# RZT2H register map
Vendor: Renesas Electronics Corporation; Series: RZT; File version: 1.00.00
CPU: other r0p0, little endian, MPU, no FPU, VTOR, 4 interrupt priority bits, 624 interrupts
Registers are 32-bit, read-write, reset 0x0 unless marked. A register's access mark holds for its fields unless they carry their own. Offsets are from the block's base; [hi:lo] are bit positions; {n}, {i} and the like mark numbered series; 'fields as' and 'values as' point back to an identical list.

## PCIE0 (part 1 of 2) — PCI Express 3.0 Interface 0
Base 0x92100000
Same registers: PCIE1 0x92110000
{0x80+4i} PCI_EP_REQDATA{i} (i=0..2) reset not defined — Request Data Register {i}
{0x80+4i} PCI_RC_REQDATA{i} (i=0..2) reset not defined (alternate view of PCI_EP_REQDATA{i}) — Request Data Register {i}
0x8C PCI_EP_REQRCVDAT ro reset not defined — Request Receive Data Register
0x8C PCI_RC_REQRCVDAT ro reset not defined (alternate view of PCI_EP_REQRCVDAT) — Request Receive Data Register
0x90 PCI_EP_REQADR1 reset not defined — Request Address Register 1
0x90 PCI_RC_REQADR1 reset not defined (alternate view of PCI_EP_REQADR1) — Request Address Register 1
0x94 PCI_EP_REQADR2 reset not defined — Request Address Register 2
0x94 PCI_RC_REQADR2 reset not defined (alternate view of PCI_EP_REQADR2) — Request Address Register 2
0x98 PCI_EP_REQBE reset 0xF — Request Byte Enable Register
  [3:0] RBE — Request Byte Enable
    0=Byte Enable enabled; 1=Byte Enable disabled
0x98 PCI_RC_REQBE reset 0xF (alternate view of PCI_EP_REQBE) — Request Byte Enable Register
  fields as PCI_EP_REQBE
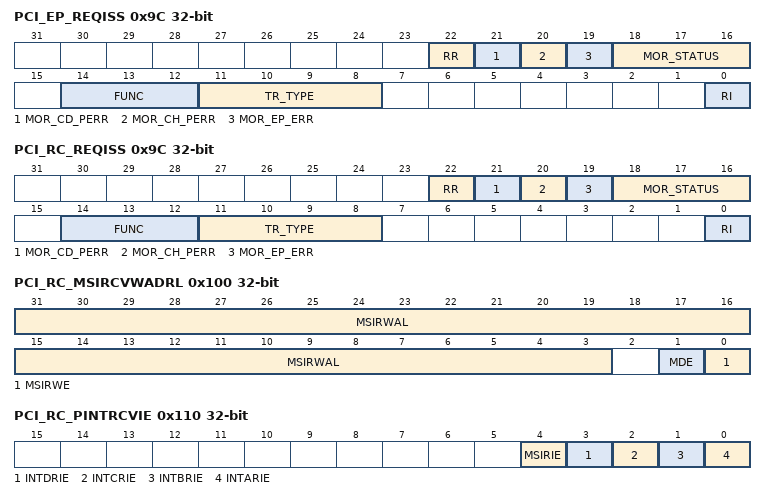
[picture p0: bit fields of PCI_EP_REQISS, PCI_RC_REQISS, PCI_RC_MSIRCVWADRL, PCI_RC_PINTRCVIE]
0x9C PCI_EP_REQISS — Request Issue Register
  [22] RR ro — Request Rejection
    0=Normal state (Request issued); 1=Rejection
  [21] MOR_CD_PERR ro — It is set to 1 when a data error occurs in the Completion TLP for the Non-Posted request issued by this register.
  [20] MOR_CH_PERR ro — It is set to 1 when a header error occurs in the Completion TLP for the Non-Posted request issued by this register.
  [19] MOR_EP_ERR ro — It is set to 1 when a Poisoned Completion TLP for a Non-Posted request issued by this register is received.
  [18:16] MOR_STATUS ro — These bits retain the MOR Status of Completion TLP for Non-Posted requests issued.
    0=Successful Completion (SC); 1=Unsupported Request (UR); 2=Configuration Request Retry Status (CRS) (not supported); 3=Completion Timeout; 4=Completer Abort (CA); 5=Unexpected Completion and mismatched type (Lock Completion responds to non-Lock Request); 7=Overrun Completion length
  [14:12] FUNC — Set the function of Request.
  [11:8] TR_TYPE — Set the type of Request.
  [0] RI — Request Issue
    0=Write: No operation. Read: Request can be accepted. (Indicates that the processing of the issued Request has ended.); 1=Write: Request issuance. Read: Processing Request. (Indicates that the issued Request is being processed.)
0x9C PCI_RC_REQISS (alternate view of PCI_EP_REQISS) — Request Issue Register
  fields as PCI_EP_REQISS
0x100 PCI_RC_MSIRCVWADRL — MSI Receive Window Address (Lower) Register
  [31:3] MSIRWAL — MSI Receive Window Address (Lower)
  [1] MDE — Message Data Enabled
    1=Used (multiple interrupts)
  [0] MSIRWE — MSI Receive Window Enable
    0=Window is disabled; 1=Window is enabled
0x104 PCI_RC_MSIRCVWADRU — MSI Receive Window Address (Upper) Register
  [31:0] MSIRWAU — MSI Receive Window Address (Upper)
0x108 PCI_RC_MSIRCVWMSKL reset 0x3 — MSI Receive Window Mask (Lower) Register
  [31:0] MSIRWML — MSI Receive Window Mask (Lower)
0x10C PCI_RC_MSIRCVWMSKU — MSI Receive Window Mask (Upper) Register
  [30:0] MSIRWMU — MSI Receive Window Mask (Upper)
0x110 PCI_RC_PINTRCVIE — PCI INTx Receive Interrupt Enable Register
  [all] fields
    0=disable; 1=enable
  [4] MSIRIE — MSI Receive Interrupt Enable
  [3] INTDRIE — INTD Receive Interrupt Enable
  [2] INTCRIE — INTC Receive Interrupt Enable
  [1] INTBRIE — INTB Receive Interrupt Enable
  [0] INTARIE — INTA Receive Interrupt Enable
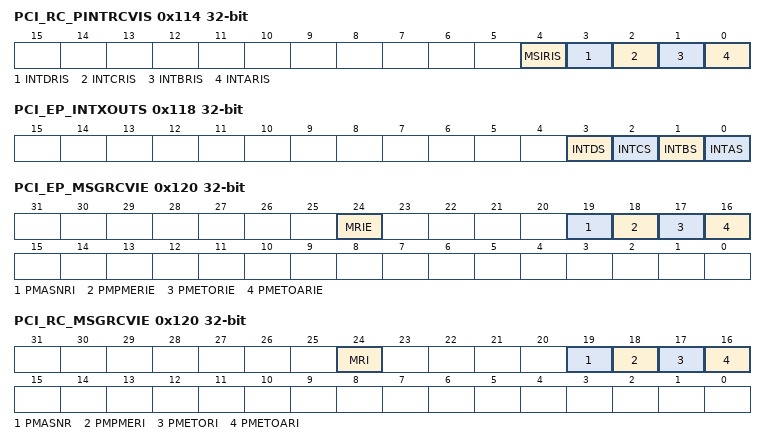
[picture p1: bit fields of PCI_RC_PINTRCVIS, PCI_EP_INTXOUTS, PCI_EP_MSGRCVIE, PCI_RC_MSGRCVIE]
0x114 PCI_RC_PINTRCVIS — PCI INTx Receive Interrupt Status Register
  [4] MSIRIS — MSI Receive Interrupt Status
  [3] INTDRIS — INTD Receive Interrupt Status
  [2] INTCRIS — INTC Receive Interrupt Status
  [1] INTBRIS — INTB Receive Interrupt Status
  [0] INTARIS — INTA Receive Interrupt Status
0x118 PCI_EP_INTXOUTS ro — PCI INTx Out Status Register
  [all] fields
    0=Deassert; 1=Assert
  [3] INTDS — INTD Status
  [2] INTCS — INTC Status
  [1] INTBS — INTB Status
  [0] INTAS — INTA Status
0x120 PCI_EP_MSGRCVIE — Message Receive Interrupt Enable Register
  [24] MRIE — Message Receive Interrupt Enable
    0=enable; 1=disable
  [19] PMASNRI — PM_Active_State_Nak Receive Interrupt
    0=Disable; 1=Enable
  [18] PMPMERIE — PM_PME Receive Interrupt Enable
    0=Disable; 1=Enable
  [17] PMETORIE — PME_Turn_Off Receive Interrupt Enable
    0=Disable; 1=Enable
  [16] PMETOARIE — PME_TO_Ack Receive Interrupt Enable
    0=Disable; 1=Enable
0x120 PCI_RC_MSGRCVIE (alternate view of PCI_EP_MSGRCVIE) — Message Receive Interrupt Enable Register
  [24] MRI — Message Receive Interrupt
    0=enable; 1=disable
  [19] PMASNR — PM_Active_State_Nak Receive
    0=Disable; 1=Enable
  [18] PMPMERI — PM_PME Receive Interrupt
    0=Disable; 1=Enable
  [17] PMETORI — PME_Turn_Off Receive Interrupt
    0=Disable; 1=Enable
  [16] PMETOARI — PME_TO_Ack Receive Interrupt
    0=Disable; 1=Enable
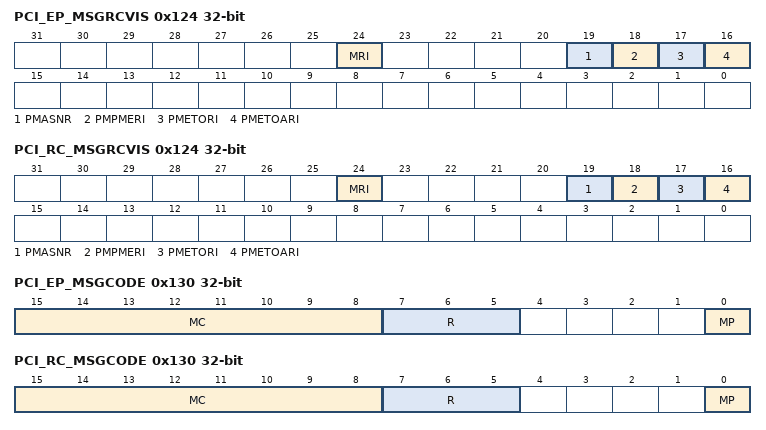
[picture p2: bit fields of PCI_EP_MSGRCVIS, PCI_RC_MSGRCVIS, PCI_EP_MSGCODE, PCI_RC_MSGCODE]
0x124 PCI_EP_MSGRCVIS — Message Receive Interrupt Status Register
  [24] MRI — Message Receive Interrupt
  [19] PMASNR — PM_Active_State_Nak Receive
  [18] PMPMERI — PM_PME Receive Interrupt
  [17] PMETORI — PME_Turn_Off Receive Interrupt
  [16] PMETOARI — PME_TO_Ack Receive Interrupt
0x124 PCI_RC_MSGRCVIS (alternate view of PCI_EP_MSGRCVIS) — Message Receive Interrupt Status Register
  fields as PCI_EP_MSGRCVIS
0x130 PCI_EP_MSGCODE ro — Message Code Register
  [15:8] MC — Message Code
  [7:5] R — Routing
  [0] MP — Message Payload
    0=Msg (Without Payload); 1=MsgD (with Payload)
0x130 PCI_RC_MSGCODE ro (alternate view of PCI_EP_MSGCODE) — Message Code Register
  fields as PCI_EP_MSGCODE
0x134 PCI_EP_MSGDATA ro — Message Data Register
0x134 PCI_RC_MSGDATA ro (alternate view of PCI_EP_MSGDATA) — Message Data Register
0x138 PCI_EP_MSGH3DW ro — Message Header 3rdDW Register
0x138 PCI_RC_MSGH3DW ro (alternate view of PCI_EP_MSGH3DW) — Message Header 3rdDW Register
0x13C PCI_EP_MSGH4DW ro — Message Header 4thDW Register
0x13C PCI_RC_MSGH4DW ro (alternate view of PCI_EP_MSGH4DW) — Message Header 4thDW Register
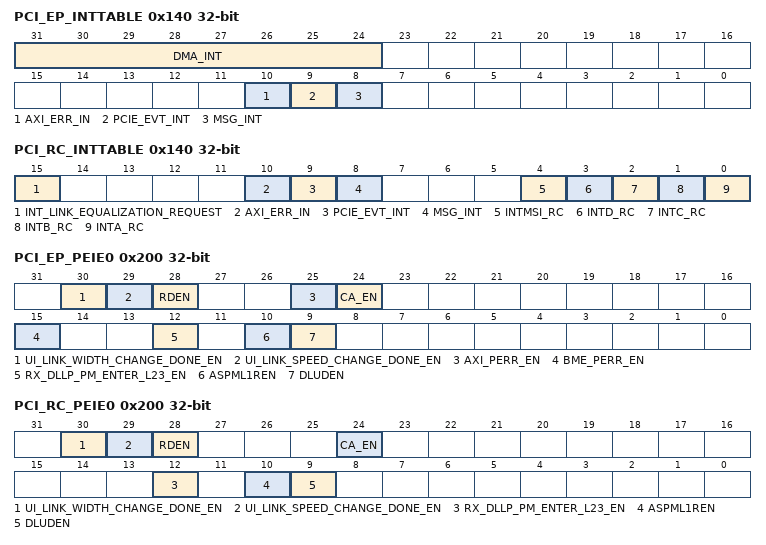
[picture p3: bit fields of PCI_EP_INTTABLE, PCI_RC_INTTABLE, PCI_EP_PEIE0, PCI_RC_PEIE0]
0x140 PCI_EP_INTTABLE ro — Interrupt Table Register
  [31:24] DMA_INT — DMA_INT interrupt signal monitor
  [10] AXI_ERR_IN — Error interrupt signal monitor
  [9] PCIE_EVT_INT — Event interrupt signal monitor
  [8] MSG_INT — Message interrupt signal monitor
0x140 PCI_RC_INTTABLE ro (alternate view of PCI_EP_INTTABLE) — Interrupt Table Register
  [15] INT_LINK_EQUALIZATION_REQUEST — LINK_EQUALIZATION_REQUEST Interrupt signal level monitor
  [10] AXI_ERR_IN — Error interrupt signal monitor
  [9] PCIE_EVT_INT — Event interrupt signal monitor
  [8] MSG_INT — Message interrupt signal monitor
  [4] INTMSI_RC — INT_MSI interrupt signal monitor
  [3] INTD_RC — INTD_RC interrupt signal monitor
  [2] INTC_RC — INTC_RC interrupt signal monitor
  [1] INTB_RC — INTB_RC interrupt signal monitor
  [0] INTA_RC — INTA_RC interrupt signal monitor
0x200 PCI_EP_PEIE0 — PCIe Event Interrupt Enable 0 Register
  [all] fields
    0=Disable; 1=Enable
  [30] UI_LINK_WIDTH_CHANGE_DONE_EN — Up/Down Configure operation complete interrupt enable
  [29] UI_LINK_SPEED_CHANGE_DONE_EN — Speed change operation completion interrupt enable
  [28] RDEN — Request complete interrupt enable
  [25] AXI_PERR_EN — Enable AXIM RAM parity error interrupt
  [24] CA_EN — CA (Completer Abort) interrupt enable
  [15] BME_PERR_EN — Enable BME Parity Error interrupt.
  [12] RX_DLLP_PM_ENTER_L23_EN — RX_DLLP_PM_ENTER_L23 interrupt enable
  [10] ASPML1REN — ASPM L1 Rejected interrupt enable
  [9] DLUDEN — DL_UpDown EN
0x200 PCI_RC_PEIE0 (alternate view of PCI_EP_PEIE0) — PCIe Event Interrupt Enable 0 Register
  [all] fields
    0=Disable; 1=Enable
  [30] UI_LINK_WIDTH_CHANGE_DONE_EN — Up/Down Configure operation complete interrupt enable
  [29] UI_LINK_SPEED_CHANGE_DONE_EN — Speed change operation completion interrupt enable
  [28] RDEN — Request complete interrupt enable
  [24] CA_EN — CA (Completer Abort) interrupt enable
  [12] RX_DLLP_PM_ENTER_L23_EN — RX_DLLP_PM_ENTER_L23 interrupt enable
  [10] ASPML1REN — ASPM L1 Rejected interrupt enable
  [9] DLUDEN — DL_UpDown EN
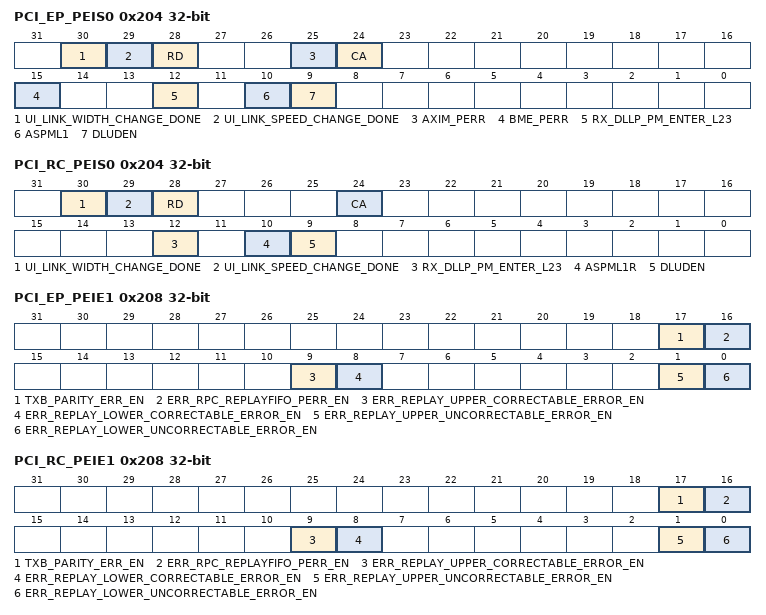
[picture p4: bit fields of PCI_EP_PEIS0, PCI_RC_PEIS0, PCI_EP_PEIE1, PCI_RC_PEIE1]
0x204 PCI_EP_PEIS0 — PCIe Event Interrupt Status 0 Register
  [30] UI_LINK_WIDTH_CHANGE_DONE — Indicates completion of Up/DownConfigure operation.
  [29] UI_LINK_SPEED_CHANGE_DONE — Indicates completion of Speed Change operation.
  [28] RD — Request Done
  [25] AXIM_PERR — Indicates that a parity error has occurred in the AXIM RAM.
  [24] CA — Indicates that the device has responded with CA (Completer Abort).
  [15] BME_PERR — Indicates that a parity error has occurred in the BME RAM.
  [12] RX_DLLP_PM_ENTER_L23 — Indicates transition to L2/L3 State in Power Management control.
  [10] ASPML1
  [9] DLUDEN — DL_UpDown EN
0x204 PCI_RC_PEIS0 (alternate view of PCI_EP_PEIS0) — PCIe Event Interrupt Status 0 Register
  [30] UI_LINK_WIDTH_CHANGE_DONE — Indicates completion of Up/DownConfigure operation.
  [29] UI_LINK_SPEED_CHANGE_DONE — Indicates completion of Speed Change operation.
  [28] RD — Request Done
  [24] CA — Indicates that the device has responded with CA (Completer Abort).
  [12] RX_DLLP_PM_ENTER_L23 — Indicates transition to L2/L3 State in Power Management control.
  [10] ASPML1R — ASPM L1 Rejected
  [9] DLUDEN — DL_UpDown EN
0x208 PCI_EP_PEIE1 — PCIe Event Interrupt Enable 1 Register
  [17] TXB_PARITY_ERR_EN — Enable the TXB_PARITY_ERR interrupt.
    0=Do not allow; 1=Allow
  [16] ERR_RPC_REPLAYFIFO_PERR_EN — Enable ERR_RPC_REPLAYFIFO_PERR interrupts.
    0=Disable; 1=Enable
  [9] ERR_REPLAY_UPPER_CORRECTABLE_ERROR_EN — Enable ERR_REPLAY_UPPER_CORRECTABLE_ERROR interrupts.
    0=Disable; 1=Enable
  [8] ERR_REPLAY_LOWER_CORRECTABLE_ERROR_EN — Enable ERR_REPLAY_LOWER_CORRECTABLE_ERROR interrupts.
    0=Disable; 1=Enable
  [1] ERR_REPLAY_UPPER_UNCORRECTABLE_ERROR_EN — Enable ERR_REPLAY_UPPER_UNCORRECTABLE_ERROR interrupts.
    0=Disable; 1=Enable
  [0] ERR_REPLAY_LOWER_UNCORRECTABLE_ERROR_EN — Enable ERR_REPLAY_LOWER_UNCORRECTABLE_ERROR interrupts.
    0=Disable; 1=Enable
0x208 PCI_RC_PEIE1 (alternate view of PCI_EP_PEIE1) — PCIe Event Interrupt Enable 1 Register
  fields as PCI_EP_PEIE1
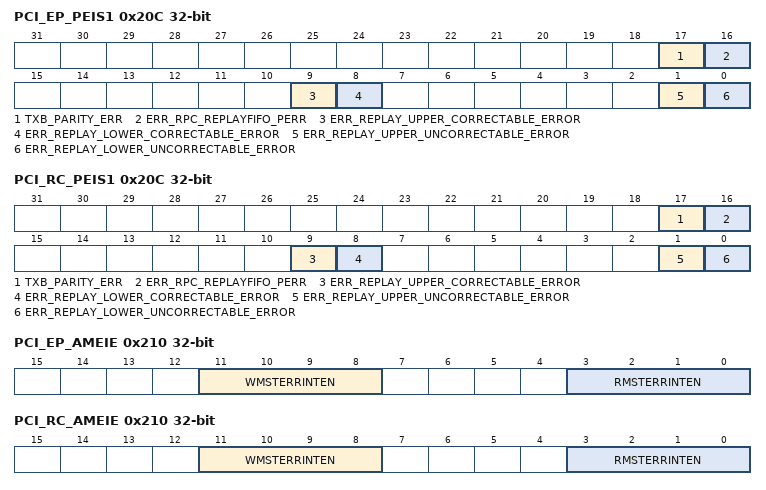
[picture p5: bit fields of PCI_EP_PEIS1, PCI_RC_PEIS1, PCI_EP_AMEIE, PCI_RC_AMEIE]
0x20C PCI_EP_PEIS1 — PCIe Event Interrupt Status 1 Register
  [17] TXB_PARITY_ERR — TXB_PARITY_ERR interrupt
  [16] ERR_RPC_REPLAYFIFO_PERR — ERR_RPC_REPLAYFIFO_PERR interrupt
  [9] ERR_REPLAY_UPPER_CORRECTABLE_ERROR — ERR_REPLAY_UPPER_CORRECTABLE_ERROR interrupt
  [8] ERR_REPLAY_LOWER_CORRECTABLE_ERROR — ERR_REPLAY_LOWER_CORRECTABLE_ERROR interrupt
  [1] ERR_REPLAY_UPPER_UNCORRECTABLE_ERROR — ERR_REPLAY_UPPER_UNCORRECTABLE_ERROR interrupt
  [0] ERR_REPLAY_LOWER_UNCORRECTABLE_ERROR — ERR_REPLAY_LOWER_UNCORRECTABLE_ERROR interrupt
0x20C PCI_RC_PEIS1 (alternate view of PCI_EP_PEIS1) — PCIe Event Interrupt Status 1 Register
  fields as PCI_EP_PEIS1
0x210 PCI_EP_AMEIE — AXI Master Error Interrupt Enable Register
  [11:8] WMSTERRINTEN — Write MSTERR INT Enable
    0=Disable; 1=Enable
  [3:0] RMSTERRINTEN — Read MSTERR INT Enable
    0=Disable; 1=Enable
0x210 PCI_RC_AMEIE (alternate view of PCI_EP_AMEIE) — AXI Master Error Interrupt Enable Register
  fields as PCI_EP_AMEIE
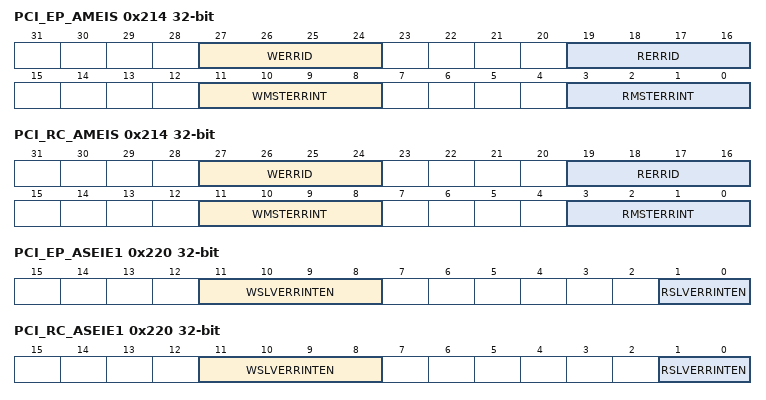
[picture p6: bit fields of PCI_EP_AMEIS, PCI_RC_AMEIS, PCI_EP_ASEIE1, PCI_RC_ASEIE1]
0x214 PCI_EP_AMEIS — AXI Master Error Interrupt Status Register
  [27:24] WERRID ro — Write ERR ID
    0=normal access; other=Others (Error ID)
  [19:16] RERRID ro — Read ERR ID
    0=normal access; other=Others (Error ID)
  [11:8] WMSTERRINT — Write MSTERR INT
  [3:0] RMSTERRINT — Read MSTERR INT
0x214 PCI_RC_AMEIS (alternate view of PCI_EP_AMEIS) — AXI Master Error Interrupt Status Register
  fields as PCI_EP_AMEIS
0x220 PCI_EP_ASEIE1 — AXI Slave Error Interrupt Enable 1 Register
  [11:8] WSLVERRINTEN — Write SLVERR INT EN
    0=Disable; 1=Enable
  [1:0] RSLVERRINTEN — Read SLVERR INT EN
    0=Disable; 1=Enable
0x220 PCI_RC_ASEIE1 (alternate view of PCI_EP_ASEIE1) — AXI Slave Error Interrupt Enable 1 Register
  fields as PCI_EP_ASEIE1
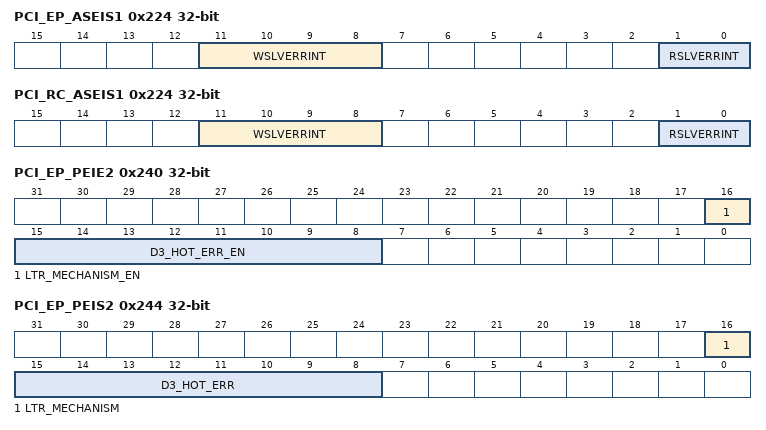
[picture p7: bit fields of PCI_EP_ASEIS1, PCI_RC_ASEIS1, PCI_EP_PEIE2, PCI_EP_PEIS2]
0x224 PCI_EP_ASEIS1 — AXI Slave Error Interrupt Status 1 Register
  [11:8] WSLVERRINT — Write SLVERR INT
  [1:0] RSLVERRINT — Read SLVERR INT
0x224 PCI_RC_ASEIS1 (alternate view of PCI_EP_ASEIS1) — AXI Slave Error Interrupt Status 1 Register
  fields as PCI_EP_ASEIS1
0x230 PCI_EP_ASEIS3 ro — AXI Slave Error Interrupt Status 3 Register
0x230 PCI_RC_ASEIS3 ro (alternate view of PCI_EP_ASEIS3) — AXI Slave Error Interrupt Status 3 Register
0x240 PCI_EP_PEIE2 — PCIe Event Interrupt Enable 2 Register
  [16] LTR_MECHANISM_EN — Interrupt enable for the ability to detect changes in CFG_LTR_MECHANISM
  [15:8] D3_HOT_ERR_EN
0x244 PCI_EP_PEIS2 — PCIe Event Interrupt Status 2 Register
  [16] LTR_MECHANISM — Status to detect and notify changes in CFG_LTR_MECHANISM
  [15:8] D3_HOT_ERR
0x300 PCI_EP_PERM — Permission Register
  [1] PHY_REG_CLK_EN — Write enable for Physical Layer Control/Status Registers.
    0=Disable; 1=Enable
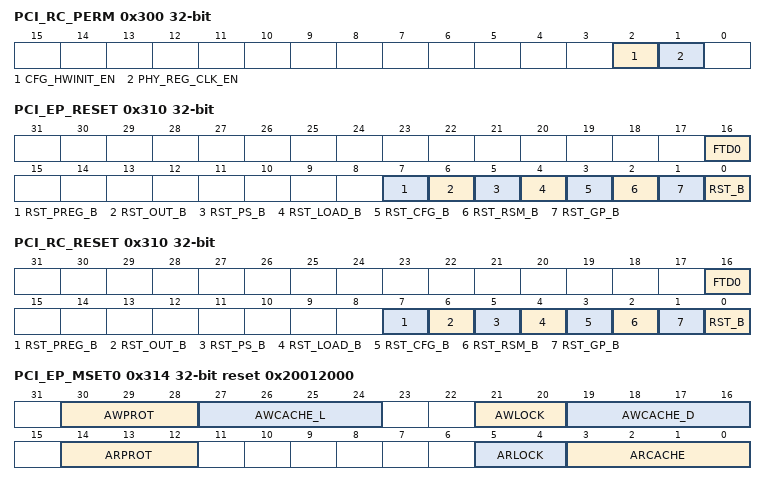
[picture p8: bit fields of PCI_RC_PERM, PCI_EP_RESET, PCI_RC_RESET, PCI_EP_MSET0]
0x300 PCI_RC_PERM (alternate view of PCI_EP_PERM) — Permission Register
  [2] CFG_HWINIT_EN — Enable HwInit attribute registers to be rewritten from AXI.
    0=Disable; 1=Enable
  [1] PHY_REG_CLK_EN — Write enable for Physical Layer Control/Status Registers.
    0=Disable; 1=Enable
0x310 PCI_EP_RESET (reset mask 0xFFFFFF00) — Reset Register
  [16] FTD0 — force to D0
    0=No operation; 1=Transition to D0
  [7] RST_PREG_B — Not used in this macro. The setting value does not affect macro behavior.
    0=reset; 1=normal operation
  [6] RST_OUT_B — RST_OUT_B output
    0=reset; 1=normal operation
  [5] RST_PS_B — Reset to the PCI Express core part (PCLK domain) inside the macro
    0=reset; 1=normal operation
  [4] RST_LOAD_B — Reset to Configuration Register
    0=reset; 1=normal operation
  [3] RST_CFG_B — Reset to Configuration Register
    0=Reset; 1=normal operation
  [2] RST_RSM_B — POWERGOOD reset of AUX Power (AUX not supported)
    0=reset; 1=normal operation
  [1] RST_GP_B — Reset to the PCI Express core part (ACLK domain) inside the macro
    0=reset; 1=normal operation
  [0] RST_B — Reset to PCI Express core part inside macro
    0=reset; 1=normal operation
0x310 PCI_RC_RESET (alternate view of PCI_EP_RESET) — Reset Register
  fields as PCI_EP_RESET
0x314 PCI_EP_MSET0 reset 0x20012000 — Mode Set 0 Register
  [30:28] AWPROT — Sets the protection type for PCIe->AXI transactions.
  [27:24] AWCACHE_L — Indicates the value of MAWCACHE[3:0] to be issued to AXI.
  [21:20] AWLOCK — Lock type for PCIe-to-AXI transactions.
    0=Normal access; 1=Exclusive access; 2=Locked access
  [19:16] AWCACHE_D — Indicates the value of MAWCACHE[3:0] to be issued to AXI.
  [14:12] ARPROT — Sets the protection type for PCIe->AXI transactions.
  [5:4] ARLOCK — Lock type for PCIe-to-AXI transactions. This bit provides information about the atomic nature of the transfer.
    0=Normal access; 1=Exclusive access; 2=Locked access
  [3:0] ARCACHE — Lock type for PCIe-to-AXI transactions. This bit provides information about the atomic nature of the transfer.
    0=Normal access; 1=Exclusive access; 2=Locked access
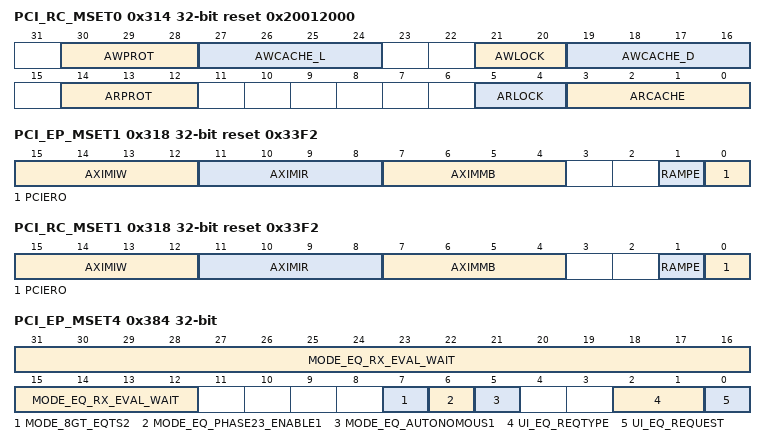
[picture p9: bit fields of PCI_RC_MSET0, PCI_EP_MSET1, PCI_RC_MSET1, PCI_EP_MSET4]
0x314 PCI_RC_MSET0 reset 0x20012000 (alternate view of PCI_EP_MSET0) — Mode Set 0 Register
  fields as PCI_EP_MSET0
0x318 PCI_EP_MSET1 reset 0x33F2 — Mode Set 1 Register
  [15:12] AXIMIW — AXI Max Issue Write
  [11:8] AXIMIR — AXI Max Issue Read
  [7:4] AXIMMB — AXI Master Max Burst
  [1] RAMPE — RAM Parity Enable
    0=RAM parity check disabled; 1=RAM parity check enabled
  [0] PCIERO — PCIe Request Order
    0=Do not wait for Completion; 1=Wait for Completion
0x318 PCI_RC_MSET1 reset 0x33F2 (alternate view of PCI_EP_MSET1) — Mode Set 1 Register
  fields as PCI_EP_MSET1
0x380 PCI_EP_MSET3 — Mode Set 3 Register
  [7:0] ASPML1IT — ASPM L1 Idle Time
0x380 PCI_RC_MSET3 (alternate view of PCI_EP_MSET3) — Mode Set 3 Register
  [7:0] ASPML1IT — ASPM L1 Idle Time
0x384 PCI_EP_MSET4 — Mode Set 4 Register
  [31:12] MODE_EQ_RX_EVAL_WAIT — During RxEval (Downstream Port Phase3, Upstream Port Phase2), wait time setting until RxEval is executed when Block Alignment cannot be obtained.
  [7] MODE_8GT_EQTS2 — 8GT EQ TS2OS transmission enable/disable setting for Upstream Port
    0=Do not send; 1=Send
  [6] MODE_EQ_PHASE23_ENABLE1 — Fixed 0
  [5] MODE_EQ_AUTONOMOUS1 — Fixed 0
  [2:1] UI_EQ_REQTYPE — Operation specification when sending Equalization Request with Quiesce Guarantee = 1 in Recovery.RcvrCfg state
    0=Equalization Request transmission with Equalization Request Data Rate = 0 (8G); 1=Send Equalization Request with Equalization Request Data Rate = 1 (16G) (Setting prohibited); 2=Operation of 0 + set Link Equalization Request 8.0 GT/s register; 3=Set 1 operation + Link Equalization Request 16.0 GT/s register (setting prohibited)
  [0] UI_EQ_REQUEST — Set when sending an Equalization Request with Quiesce Guarantee = 1 in the Recovery.RcvrCfg state.
    0=Do not send Equalization Request; 1=Send Equalization Request
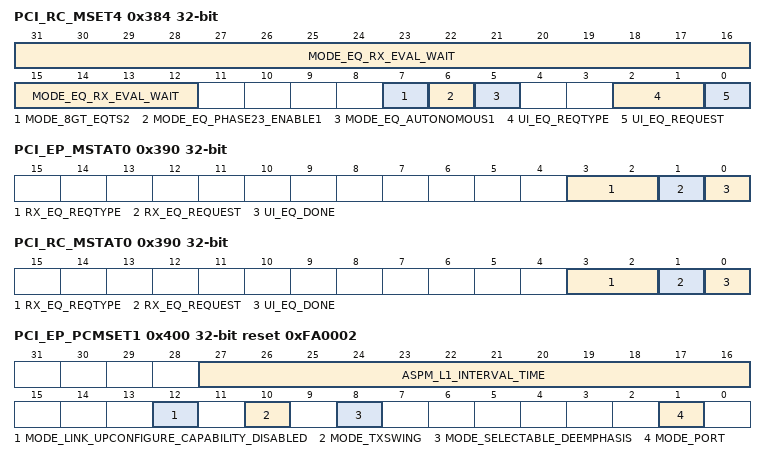
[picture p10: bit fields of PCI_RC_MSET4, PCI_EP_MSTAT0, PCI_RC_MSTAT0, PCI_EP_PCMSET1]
0x384 PCI_RC_MSET4 (alternate view of PCI_EP_MSET4) — Mode Set 4 Register
  fields as PCI_EP_MSET4
0x388 PCI_EP_MSET5 — Mode Set 5 Register
  [15:0] MODE_8GT_EQTS2_PRESET — Transmitter Preset value of 8GT EQ TS2OS to transmit at Upstream Port (USP).
0x388 PCI_RC_MSET5 (alternate view of PCI_EP_MSET5) — Mode Set 5 Register
  fields as PCI_EP_MSET5
0x390 PCI_EP_MSTAT0 ro — Mode Status 0 Register
  [3:2] RX_EQ_REQTYPE — Quiesce Guarantee and Equalization Request Data Rate bit display when receiv ing 8 consecutive TS2OS with Request Equalization bit (Symbol6, bit7) = 1 in Recovery.RcvrCfg state
  [1] RX_EQ_REQUEST — Status display when receiving 8 consecutive TS2OS with Request Equalization bit (Symbol6, bit7) = 1 in Recovery.RcvrCfg state
    0=No Equalization Request received; 1=Equalization Request received
  [0] UI_EQ_DONE — Set Equalization Request with Quiesce Guarantee=1 in Recovery .RcvrCfg state when sending
    0=No Equalization Request sent; 1=Sent Equalization Request
0x390 PCI_RC_MSTAT0 ro (alternate view of PCI_EP_MSTAT0) — Mode Status 0 Register
  fields as PCI_EP_MSTAT0
0x400 PCI_EP_PCMSET1 reset 0xFA0002 — PCIe Core Mode Set 1 Register
  [27:16] ASPM_L1_INTERVAL_TIME — Interval settings for ASPM L1 requests
  [12] MODE_LINK_UPCONFIGURE_CAPABILITY_DISABLED — Setting of Link Upconfigure Capability bit of Training Sequence Ordered-set (TS-OS)
    0=Link Upconfigure Capability bit = 1 setting; 1=Link Upconfigure Capability bit = 0 setting (Gen1 x1)
  [10] MODE_TXSWING — SerDes serial output amplitude control
    0=Full swing mode (default); 1=Half swing mode
  [8] MODE_SELECTABLE_DEEMPHASIS — For Endpoint, set the De-emphasis value for 5.0 GT/s operation. Initial value of select_deemphasis variable described in PCIe Base Spec.
    0=-6 dB (default); 1=-3.5dB
  [1] MODE_PORT — Device type setting register.
    0=Endpoint; 1=Root Complex
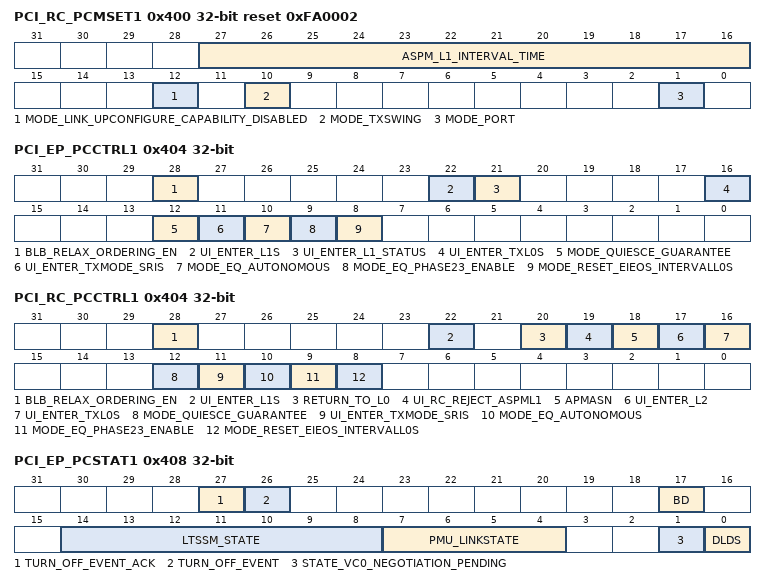
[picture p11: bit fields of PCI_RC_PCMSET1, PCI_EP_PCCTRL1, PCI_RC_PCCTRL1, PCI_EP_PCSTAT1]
0x400 PCI_RC_PCMSET1 reset 0xFA0002 (alternate view of PCI_EP_PCMSET1) — PCIe Core Mode Set 1 Register
  [27:16] ASPM_L1_INTERVAL_TIME — Interval settings for ASPM L1 requests
  [12] MODE_LINK_UPCONFIGURE_CAPABILITY_DISABLED — Setting of Link Upconfigure Capability bit of Training Sequence Ordered-set (TS-OS)
    values as PCI_EP_PCMSET1.MODE_LINK_UPCONFIGURE_CAPABILITY_DISABLED
  [10] MODE_TXSWING — SerDes serial output amplitude control
    0=Full swing mode (default); 1=Half swing mode
  [1] MODE_PORT — Device type setting register.
    0=Endpoint; 1=Root Complex
0x404 PCI_EP_PCCTRL1 — PCIe Core Control 1 Register
  [28] BLB_RELAX_ORDERING_EN — Control of RO bit of Request to be sent
    0=RO bit of Request TLP to be sent is always 0 (default); 1=A TLP can be sent with the RO bit of the Request TLP to be sent set to 1
  [22] UI_ENTER_L1S — L1SubState transition permission setting
    0=L1SubState transition disabled (default); 1=L1SubState transition permission (setting prohibited)
  [21] UI_ENTER_L1_STATUS — L1 transition status
    0=Normal operation (default); 1=L1 transition processing
  [16] UI_ENTER_TXL0S — TxL0s transition control
    0=Do not perf orm ASPM L0s transition (default); 1=Execute ASPM L0s transition when internal conditions are satisfied
  [12] MODE_QUIESCE_GUARANTEE — Symbol6 bit6 Quiesce Guarantee control bit of TS2OS
    0=Set 0 to TS2OS (default); 1=Set 1 to TS2OS
  [11] UI_ENTER_TXMODE_SRIS — Setting Clock Tolerance Compensation
    0=SRNS (default); 1=SRIS (not supported)
  [10] MODE_EQ_AUTONOMOUS — Gen3 feature: Autonomous Equalization
    0=Do not use Autonomous Mechanism; 1=Use Autonomous Mechanisms
  [9] MODE_EQ_PHASE23_ENABLE — Gen3 features:
    0=Do not execute EQ PHASE2/3; 1=Execute EQ PHASE2/3
  [8] MODE_RESET_EIEOS_INTERVALL0S — Gen3 features:
0x404 PCI_RC_PCCTRL1 (alternate view of PCI_EP_PCCTRL1) — PCIe Core Control 1 Register
  [28] BLB_RELAX_ORDERING_EN — Control of RO bit of Request to be sent
    values as PCI_EP_PCCTRL1.BLB_RELAX_ORDERING_EN
  [22] UI_ENTER_L1S — L1SubState transition permission setting
    values as PCI_EP_PCCTRL1.UI_ENTER_L1S
  [20] RETURN_TO_L0 — RC mode L1, L2 state to L0 state control (usually not used)
    0=Normal operation (default); 1=Start return operation to L0 state when in L1 or L2 state in RC mode
  [19] UI_RC_REJECT_ASPML1 — ASPM L1 transition rejection control
    0=Accept ASPM L1 transition request from EP device (default); 1=Reject ASPM L1 transition request from EP device
  [18] APMASN — Auto PM_Active_State_Nak
  [17] UI_ENTER_L2 — RC mode L2 transition control
  [16] UI_ENTER_TXL0S — TxL0s transition control
    values as PCI_EP_PCCTRL1.UI_ENTER_TXL0S
  [12] MODE_QUIESCE_GUARANTEE — Symbol6 bit6 Quiesce Guarantee control bit of TS2OS
    0=Set 0 to TS2OS (default); 1=Set 1 to TS2OS
  [11] UI_ENTER_TXMODE_SRIS — Setting Clock Tolerance Compensation
    0=SRNS (default); 1=SRIS (not supported)
  [10] MODE_EQ_AUTONOMOUS — Gen3 feature: Autonomous Equalization
    values as PCI_EP_PCCTRL1.MODE_EQ_AUTONOMOUS
  [9] MODE_EQ_PHASE23_ENABLE — Gen3 features:
    0=Do not execute EQ PHASE2/3; 1=Execute EQ PHASE2/3
  [8] MODE_RESET_EIEOS_INTERVALL0S — Gen3 features:
0x408 PCI_EP_PCSTAT1 ro (reset mask 0xF7FD8008) — PCIe Core Status 1 Register
  [27] TURN_OFF_EVENT_ACK
  [26] TURN_OFF_EVENT
  [17] BD — bme_down
  [14:8] LTSSM_STATE — Indicates the state of the Link Training & Status State Machine in the PCIe Core Link.
  [7:4] PMU_LINKSTATE — L-state monitor of power management control unit
    4=L1 state; 8=L2 state
  [1] STATE_VC0_NEGOTIATION_PENDING — Flow Control initialization operation monitor
    0=Indicates that Flow Control initialization is complete; 1=Indicates that Flow Control initialization has not completed
  [0] DLDS — DL_Down status
    0=DL_Up Status; 1=DL_Down Status
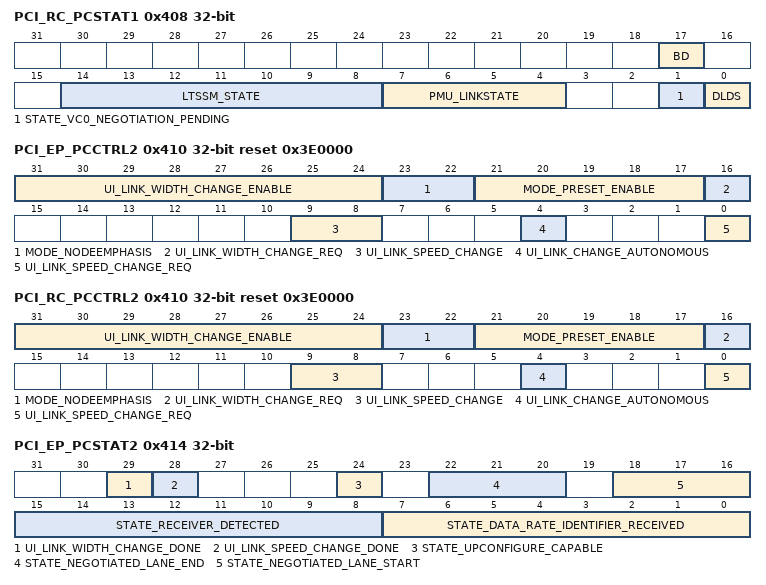
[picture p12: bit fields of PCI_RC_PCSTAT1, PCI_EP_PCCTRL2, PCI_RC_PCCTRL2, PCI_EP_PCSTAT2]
0x408 PCI_RC_PCSTAT1 ro (reset mask 0xFFFD8008) (alternate view of PCI_EP_PCSTAT1) — PCIe Core Status 1 Register
  [17] BD — bme_down
  [14:8] LTSSM_STATE — Indicates the state of the Link Training & Status State Machine in the PCIe Core Link.
  [7:4] PMU_LINKSTATE — L-state monitor of power management control unit
    4=L1 state; 8=L2 state
  [1] STATE_VC0_NEGOTIATION_PENDING — Flow Control initialization operation monitor
    values as PCI_EP_PCSTAT1.STATE_VC0_NEGOTIATION_PENDING
  [0] DLDS — DL_Down status
    0=DL_Up Status; 1=DL_Down Status
0x410 PCI_EP_PCCTRL2 reset 0x3E0000 — PCIe Core Control 2 Register
  [31:24] UI_LINK_WIDTH_CHANGE_ENABLE — Link Width setting to change
  [23:22] MODE_NODEEMPHASIS — No de-emphasis mode setting for Gen1/Gen3 operation
  [21:17] MODE_PRESET_ENABLE — Reduced Swing mode setting for Gen3 operation
  [16] UI_LINK_WIDTH_CHANGE_REQ — Link Width change request control
  [9:8] UI_LINK_SPEED_CHANGE — Link speed setting
    0=2.5 GT/s; 1=5.0 GT/s; 2=8.0 GT/s; 3=16.0 GT/s (Setting prohibited)
  [4] UI_LINK_CHANGE_AUTONOMOUS — Link Width/Speed change reason setting
    0=reliability reason (change for reliability, direction of bandwidth reduction); 1=autonomous reason (intentional change)
  [0] UI_LINK_SPEED_CHANGE_REQ — Link Speed change request control
0x410 PCI_RC_PCCTRL2 reset 0x3E0000 (alternate view of PCI_EP_PCCTRL2) — PCIe Core Control 2 Register
  [31:24] UI_LINK_WIDTH_CHANGE_ENABLE — Link Width setting to change
  [23:22] MODE_NODEEMPHASIS — No de-emphasis mode setting for Gen1/Gen2 operation
  [21:17] MODE_PRESET_ENABLE — Reduced Swing mode setting for Gen3 operation
  [16] UI_LINK_WIDTH_CHANGE_REQ — Link Width change request control
  [9:8] UI_LINK_SPEED_CHANGE — Link speed setting
    values as PCI_EP_PCCTRL2.UI_LINK_SPEED_CHANGE
  [4] UI_LINK_CHANGE_AUTONOMOUS — Link Width/Speed change reason setting
    values as PCI_EP_PCCTRL2.UI_LINK_CHANGE_AUTONOMOUS
  [0] UI_LINK_SPEED_CHANGE_REQ — Link Speed change request control
0x414 PCI_EP_PCSTAT2 ro (reset mask 0xCE880000) — PCIe Core Status 2 Register
  [29] UI_LINK_WIDTH_CHANGE_DONE — Link Width Change operation complete display
  [28] UI_LINK_SPEED_CHANGE_DONE — Link Speed Change operation complete display
  [24] STATE_UPCONFIGURE_CAPABLE — Upconfigure Capable bit display of opposite device
  [22:20] STATE_NEGOTIATED_LANE_END — Displays the position of Lane Number (n-1) (meaning Lane 1 when n=2) after Link Negotiation with the opposite device during n-lane operation.
    0=Lane 0 is Lane Number (n-1); 1=Lane 1 is Lane Number (n-1); other=Others (Reserved)
  [18:16] STATE_NEGOTIATED_LANE_START — Displays the position of Lane Number 0 after Link Negotiation with the opposite device during n-lane operation.
    0=Lane 0 is Lane Number 0; 1=Lane 1 is Lane Number 0; other=Others (Reserved)
  [15:8] STATE_RECEIVER_DETECTED — Connection status display with other device
  [7:0] STATE_DATA_RATE_IDENTIFIER_RECEIVED — Link Speed display supported by the opposite device
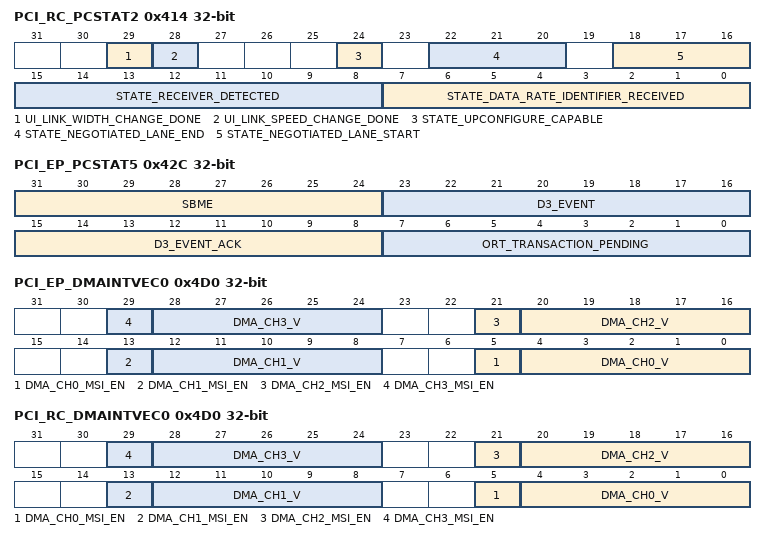
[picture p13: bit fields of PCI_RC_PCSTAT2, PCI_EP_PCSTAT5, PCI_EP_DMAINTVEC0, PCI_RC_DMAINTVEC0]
0x414 PCI_RC_PCSTAT2 ro (reset mask 0xCE880000) (alternate view of PCI_EP_PCSTAT2) — PCIe Core Status 2 Register
  fields as PCI_EP_PCSTAT2
0x42C PCI_EP_PCSTAT5 ro (reset mask 0xFFFFFCFF) — PCIe Core Status 5 Register
  [31:24] SBME — Suspend_bme
  [23:16] D3_EVENT — D3_EVENT signal monitor for each function
  [15:8] D3_EVENT_ACK — D3_EVENT_ACK signal monitor for each function
  [7:0] ORT_TRANSACTION_PENDING — Outstanding Request Monitor by Function
    0=State without Outstanding Request; 1=State with Outstanding Request
0x42C PCI_RC_PCSTAT5 ro (alternate view of PCI_EP_PCSTAT5) — PCIe Core Status 5 Register
  [1:0] ORT_TRANSACTION_PENDING — Indicates whether or not there are Outstanding Requests (a state in which all Completions corresponding to Non-Posted Requests sent from the AXI side have not been received).
    values as PCI_EP_PCSTAT5.ORT_TRANSACTION_PENDING
0x4D0 PCI_EP_DMAINTVEC0 — DMA Interrupt Vector 0 Register
  [8n+5] DMA_CH{n}_MSI_EN (n=0..3) — DMA Ch{n} MSI Enable
    0=Do not use MSI (DMA interrupt notification by DMA_INT interrupt); 1=Use MSI
  [8n+4:8n] DMA_CH{n}_V (n=0..3) — Vector value of MSI interrupt transmitted by DMAC Ch{n}
0x4D0 PCI_RC_DMAINTVEC0 (alternate view of PCI_EP_DMAINTVEC0) — DMA Interrupt Vector 0 Register
  fields as PCI_EP_DMAINTVEC0
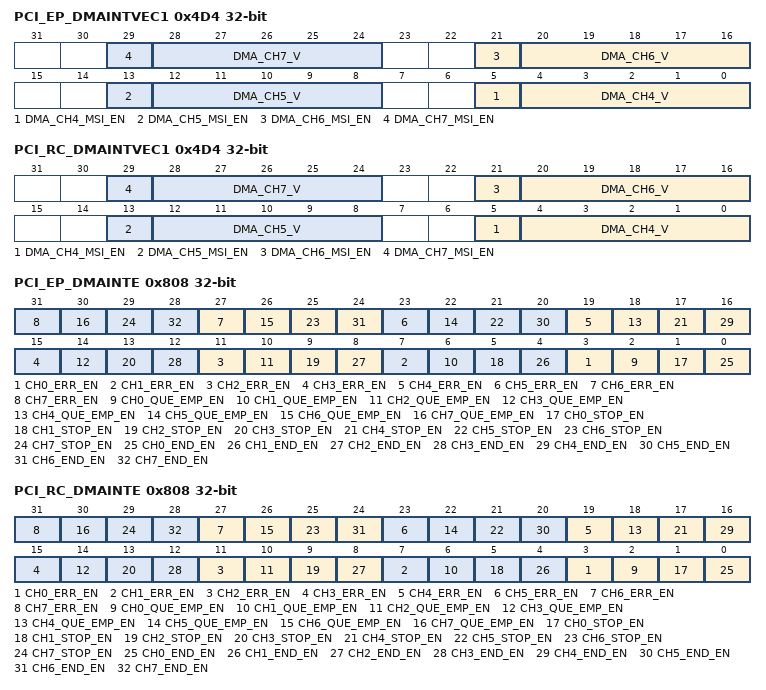
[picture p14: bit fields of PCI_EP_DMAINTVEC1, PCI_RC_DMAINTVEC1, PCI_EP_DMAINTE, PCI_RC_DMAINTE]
0x4D4 PCI_EP_DMAINTVEC1 — DMA Interrupt Vector 1 Register
  [8n-27] DMA_CH{n}_MSI_EN (n=4..7) — DMA Ch{n} MSI Enable
    values as PCI_EP_DMAINTVEC0.DMA_CH0_MSI_EN
  [8n-28:8n-32] DMA_CH{n}_V (n=4..7) — Vector value of MSI interrupt transmitted by DMAC Ch{n}
0x4D4 PCI_RC_DMAINTVEC1 (alternate view of PCI_EP_DMAINTVEC1) — DMA Interrupt Vector 1 Register
  fields as PCI_EP_DMAINTVEC1
{0x600+0x10*i} PCI_RC_MSIRCVE{i} (i=0..15) — MSI Receive Enable {i} Register
  [0] E — Enable
    0=disabled; 1=Enabled
{0x604+0x10*i} PCI_RC_MSIRCVMSGDATA{i} (i=0..15) — MSI Receive Message Data {i} Register
{0x608+0x10*i} PCI_RC_MSIRCVMSK{i} (i=0..15) reset 0xFFFFFFFF — MSI Receive Mask {i} Register
{0x60C+0x10*i} PCI_RC_MSIRCVSTAT{i} (i=0..15) — MSI Receive Status {i} Register
0x800 PCI_EP_DMACTRL — DMAC Control Register
  [2:0] D_PMRS — DMAC PCIe Max Read Request Size
    0=128 bytes (default); 1=256 bytes; 2=512 bytes (not supported); 3=1024 bytes (not supported); 4=2048 bytes (not supported); 5=4096 bytes (not supported); other=others (Reserved (prohibited))
0x800 PCI_RC_DMACTRL (alternate view of PCI_EP_DMACTRL) — DMAC Control Register
  fields as PCI_EP_DMACTRL
0x808 PCI_EP_DMAINTE — DMAC Interrupt Enable Register
  [all] fields
    0=Disable; 1=Enable
  [4n+3] CH{n}_ERR_EN (n=0..7) — CH{n} Error Interrupt Enable
  [4n+2] CH{n}_QUE_EMP_EN (n=0..7) — CH{n} Que Empty Interrupt Enable
  [4n+1] CH{n}_STOP_EN (n=0..7) — CH{n} Stop Interrupt Enable
  [4n] CH{n}_END_EN (n=0..7) — CH{n} Completion Interrupt Enable
0x808 PCI_RC_DMAINTE (alternate view of PCI_EP_DMAINTE) — DMAC Interrupt Enable Register
  fields as PCI_EP_DMAINTE
0x80C PCI_EP_DMAINTS — DMAC Interrupt Status Register
  [4n+3] CH{n}_ERR (n=0..7) — Set when an error occurs during DMA transfer.
  [4n+2] CH{n}_QUE_EMP (n=0..7) — Set when the list is removed from the descriptor queue (transferred to the execution descriptor list) and the QUE is empty.
  [4n+1] CH{n}_STOP (n=0..7) — Set when the DMAC is prematurely stopped.
  [4n] CH{n}_END (n=0..7) — Set when the DMAC ends normally.
0x80C PCI_RC_DMAINTS (alternate view of PCI_EP_DMAINTS) — DMAC Interrupt Status Register
  fields as PCI_EP_DMAINTS
{0x900+0x80*i} PCI_EP_DMACHCTL{i} (i=0..7) — DMAC Channel Control Register {i}
  [8] QUE_CLR — QUE Clear
  [1] QUE_EN — QUE Enable
  [0] RDMA_EN — Register method DMA transfer Enable
    0=Stop register-based DMA transfer; 1=Register method DMA transfer start
{0x900+0x80*i} PCI_RC_DMACHCTL{i} (i=0..7) (alternate view of PCI_EP_DMACHCTL{i}) — DMAC Channel Control Register {i}
  fields as PCI_EP_DMACHCTL0
{0x908+0x80*i} PCI_EP_DPSADRL{i} (i=0..7) — Descriptor Start Address (Lower) Register {i}
  [31:6] QUE_ENTRY_DSA3106 — Descriptor list queue registration register. This area will be the DSA.
  [5:0] QUE_ENTRY_DSA0500 ro — Descriptor list queue registration register. This area will be the DSA.
{0x908+0x80*i} PCI_RC_DPSADRL{i} (i=0..7) (alternate view of PCI_EP_DPSADRL{i}) — Descriptor Start Address (Lower) Register {i}
  fields as PCI_EP_DPSADRL0
{0x90C+0x80*i} PCI_EP_DPSADRU{i} (i=0..7) — Descriptor Start Address (Upper) Registers {i}
  [31:0] QUE_ENTRY_DSA6332 — Descriptor list queue registration register. This area will be the DSA.
{0x90C+0x80*i} PCI_RC_DPSADRU{i} (i=0..7) (alternate view of PCI_EP_DPSADRU{i}) — Descriptor Start Address (Upper) Register {i}
  fields as PCI_EP_DPSADRU0
{0x910+0x80*i} PCI_EP_QUEE{i} (i=0..7) — QUE Entry Register {i}
  [31:26] QUE_R — QUE_Registration
  [25] QUE_ENTRY_EI — Indicates whether an interrupt (Interrupt Status CHx_END) is sent when the processing of the descriptor list is completed.
    0=Do not signal interrupts; 1=signal an interrupt
  [24] QUE_ENTRY_LS — Indicates whether to stop the DMA when processing of the descriptor list is complete.
    0=do not stop; 1=stop
  [15:0] QUE_ENTRY_LABEL — There is no particular rule on how to set the labels in the list.
{0x910+0x80*i} PCI_RC_QUEE{i} (i=0..7) (alternate view of PCI_EP_QUEE{i}) — QUE Entry Register {i}
  fields as PCI_EP_QUEE0
{0x920+0x80*i} PCI_EP_DMADPCTL{i} (i=0..7) ro — DMA Descriptor Control (Descriptor 0x00) Register {i}
  [31:28] DSCFM — Shows the value of the DSCFM field in the running descriptor table.
  [26] WBD — Shows the value of the WBD field in the running descriptor table.
  [25] LE — Shows the value of the LE field in the running descriptor table.
  [24] LV — Shows the value of the LV field in the running descriptor table.
  [23] D — Shows the value of the D field in the running descriptor table.
  [15:0] STS — Shows the value of the STS field in the running descriptor table.
{0x920+0x80*i} PCI_RC_DMADPCTL{i} (i=0..7) ro (alternate view of PCI_EP_DMADPCTL{i}) — DMA Descriptor Control (Descriptor 0x00) Register {i}
  fields as PCI_EP_DMADPCTL0
{0x924+0x80*i} PCI_EP_DMATCTL{i} (i=0..7) — DMA Transaction Control (Descriptor 0x04) Register {i}
  [23:20] CCH_L — Indicates the value of A*CACHE[3:0] to be issued to AXI.
  [19:16] CCH_D — Indicates the value of A*CACHE[3:0] to be issued to AXI.
  [14:12] DMA_TC — Traffic class to publish to PCIe.
  [9:8] DMA_ATB — Attributes to publish to PCIe.
  [6:4] DMA_FUNC — Specify the function number of the request issued to PCIe.
  [0] DMA_DIR — Sets the DMA transfer direction.
    0=PCIe to AXI; 1=AXI to PCIe
{0x924+0x80*i} PCI_RC_DMATCTL{i} (i=0..7) (alternate view of PCI_EP_DMATCTL{i}) — DMA Transaction Control (Descriptor 0x04) Register {i}
  fields as PCI_EP_DMATCTL0
{0x928+0x80*i} PCI_EP_DMASIZE{i} (i=0..7) — DMA Size (Descriptor 0x08) Register {i}
  [31:4] DMA_SIZE3104 — Sets the number of DMA transfer bytes.
  [3:0] DMA_SIZE0300 ro — Sets the number of DMA transfer bytes.
{0x928+0x80*i} PCI_RC_DMASIZE{i} (i=0..7) (alternate view of PCI_EP_DMASIZE{i}) — DMA Size (Descriptor 0x08) Register {i}
  fields as PCI_EP_DMASIZE0
{0x930+0x80*i} PCI_EP_DMASLA{i} (i=0..7) — DMA Source Lower Address (Descriptor 0x10) Register {i}
  [31:4] DMA_S_ADDR3104 — Set the lower 32 bits of the transfer source start address for DMA transfer.
  [3:0] DMA_S_ADDR0300 ro — Set the lower 32 bits of the transfer source start address for DMA transfer.
{0x930+0x80*i} PCI_RC_DMASLA{i} (i=0..7) (alternate view of PCI_EP_DMASLA{i}) — DMA Source Lower Address (Descriptor 0x10) Register {i}
  fields as PCI_EP_DMASLA0
{0x934+0x80*i} PCI_EP_DMASUA{i} (i=0..7) — DMA Source Upper Address (Descriptor 0x14) Register {i}
  [31:0] DMA_S_ADDR6332 — Set the upper 32 bits of the transfer source start address for MA transfer.
{0x934+0x80*i} PCI_RC_DMASUA{i} (i=0..7) (alternate view of PCI_EP_DMASUA{i}) — DMA Source Upper Address (Descriptor 0x14) Register {i}
  fields as PCI_EP_DMASUA0
{0x938+0x80*i} PCI_EP_DMADESTLA{i} (i=0..7) — DMA Destination Lower Address (Descriptor 0x18) Register {i}
  [31:4] DMA_D_ADDR3104 — Set the lower 32 bits of the transfer destination start address for DMA transfer.
  [3:0] DMA_D_ADDR0300 ro — Set the lower 32 bits of the transfer destination start address for DMA transfer.
{0x938+0x80*i} PCI_RC_DMADESTLA{i} (i=0..7) (alternate view of PCI_EP_DMADESTLA{i}) — DMA Destination Lower Address (Descriptor 0x18) Register {i}
  fields as PCI_EP_DMADESTLA0
{0x93C+0x80*i} PCI_EP_DMADESTUA{i} (i=0..7) — DMA Destination Upper Address (Descriptor 0x1C) Register {i}
  [31:0] DMA_D_ADDR6332 — Set the upper 32 bits of the transfer destination start address for DMA transfer.
{0x93C+0x80*i} PCI_RC_DMADESTUA{i} (i=0..7) (alternate view of PCI_EP_DMADESTUA{i}) — DMA Destination Upper Address (Descriptor 0x1C) Register {i}
  fields as PCI_EP_DMADESTUA0
{0x940+0x80*i} PCI_EP_DMADPLLP{i} (i=0..7) ro — DMA Descriptor Lower Link Pointer (Descriptor 0x20) Register {i}
  [31:0] DMA_LP3100 — Indicates the value of the LP field of the running descriptor table.
{0x940+0x80*i} PCI_RC_DMADPLLP{i} (i=0..7) ro (alternate view of PCI_EP_DMADPLLP{i}) — DMA Descriptor Lower Link Pointer (Descriptor 0x20) Register {i}
  fields as PCI_EP_DMADPLLP0
{0x944+0x80*i} PCI_EP_DMADPULP{i} (i=0..7) ro — DMA Descriptor Upper Link Pointer (Descriptor 0x24) Register {i}
  [31:0] DMA_LP6332 — Indicates the value of the LP field of the running descriptor table.
{0x944+0x80*i} PCI_RC_DMADPULP{i} (i=0..7) ro (alternate view of PCI_EP_DMADPULP{i}) — DMA Descriptor Upper Link Pointer (Descriptor 0x24) Register {i}
  fields as PCI_EP_DMADPULP0
{0x950+0x80*i} PCI_EP_DMARESTSIZE{i} (i=0..7) ro — DMA Rest Size Register {i}
{0x950+0x80*i} PCI_RC_DMARESTSIZE{i} (i=0..7) ro (alternate view of PCI_EP_DMARESTSIZE{i}) — DMA Rest Size Register {i}
{0x960+0x80*i} PCI_EP_AREQAL{i} (i=0..7) ro — AXI Request Address (Lower) Register {i}
  [31:0] AXI_REQ_ADDR3100 — Displays the lower 32 bits of the address of the currently completed AXI transfer or the transfer that just completed. (Register/descriptor method common)
{0x960+0x80*i} PCI_RC_AREQAL{i} (i=0..7) ro (alternate view of PCI_EP_AREQAL{i}) — AXI Request Address (Lower) Register {i}
  fields as PCI_EP_AREQAL0
{0x964+0x80*i} PCI_EP_AREQAU{i} (i=0..7) ro — AXI Request Address (Upper) Register {i}
  [31:0] AXI_REQ_ADDR6332 — Displays the upper 32 bits of the address of the currently completed AXI transfer or the transfer that just completed. (Register/descriptor method common)
{0x964+0x80*i} PCI_RC_AREQAU{i} (i=0..7) ro (alternate view of PCI_EP_AREQAU{i}) — AXI Request Address (Upper) Register {i}
  fields as PCI_EP_AREQAU0
{0x968+0x80*i} PCI_EP_PREQAL{i} (i=0..7) ro — PCIe Request Address (Lower) Register {i}
  [31:0] PCIE_REQ_ADDR3100 — Displays the lower 32 bits of the address of the currently completed PCIe transfer or the transfer completed immediately before. (Register/descriptor method common)
{0x968+0x80*i} PCI_RC_PREQAL{i} (i=0..7) ro (alternate view of PCI_EP_PREQAL{i}) — PCIe Request Address (Lower) Register {i}
  fields as PCI_EP_PREQAL0
{0x96C+0x80*i} PCI_EP_PREQAU{i} (i=0..7) ro — PCIe Request Address (Upper) Register {i}
  [31:0] PCIE_REQ_ADDR6332 — Displays the upper 32 bits of the address of the currently completed PCIe transfer or the transfer completed immediately before. (Register/descriptor method common)
{0x96C+0x80*i} PCI_RC_PREQAU{i} (i=0..7) ro (alternate view of PCI_EP_PREQAU{i}) — PCIe Request Address (Upper) Register {i}
  fields as PCI_EP_PREQAU0
{0x970+0x80*i} PCI_EP_QUESTA{i} (i=0..7) ro — QUE Status Register {i}
  [4] GO_LIST — Shows whether there is a running descriptor list.
    0=none; 1=Yes
  [3:0] LIST_NUM — Displays the number of descriptor lists loaded on QUE (not including the list currently being executed).
{0x970+0x80*i} PCI_RC_QUESTA{i} (i=0..7) ro (alternate view of PCI_EP_QUESTA{i}) — QUE Status Register {i}
  fields as PCI_EP_QUESTA0
{0x978+0x80*i} PCI_EP_DMACESTA{i} (i=0..7) ro — DMAC Error Status Register {i}
  [18] CFG_BM_DIS_EP — CHx_ERR is set when the macro operates as an End Point and detects the state of Bus Master Enable Off (Configuration Space 0x004 bit [2] = 0). Holds value until CHx_ERR is cleared.
  [17] BME_SUP — It is set when a sleep signal from the PCIe core is detected as a cause for setting CHx_ERR. Holds value until CHx_ERR is cleared.
  [16] BME_DOWN — It is set when a stop signal from the PCIe core is detected as a cause for setting CHx_ERR. Holds value until CHx_ERR is cleared.
  [13] MOR_CD_PERR — It is set when MOR_CD_PERR is detected as a set factor for CHx_ERR. Holds value until CHx_ERR is cleared.
  [12] MOR_CH_PERR — It is set when MOR_CH_PERR is detected as a set factor for CHx_ERR. Holds value until CHx_ERR is cleared.
  [11] MOR_EP_ERR — It is set when it is Poisoned Completion as a set factor of CHx_ERR. Holds value until CHx_ERR is cleared.
  [10:8] MOR_STATUS — Indicates the value when MOR_STATUS is other than 000b (Success) as a set factor of CHx_ERR. Holds value until CHx_ERR is cleared.
    0=initial value; 1=Unsupported Request; 2=CRS; 3=Completion Timeout; 4=Completer Abort; 5=Unexpected Completion; 7=Mismatched Length (Length Overrun)
  [1:0] AXI_RESP — Displays the slave response during AXI Master transactions.
    0=Initial value
